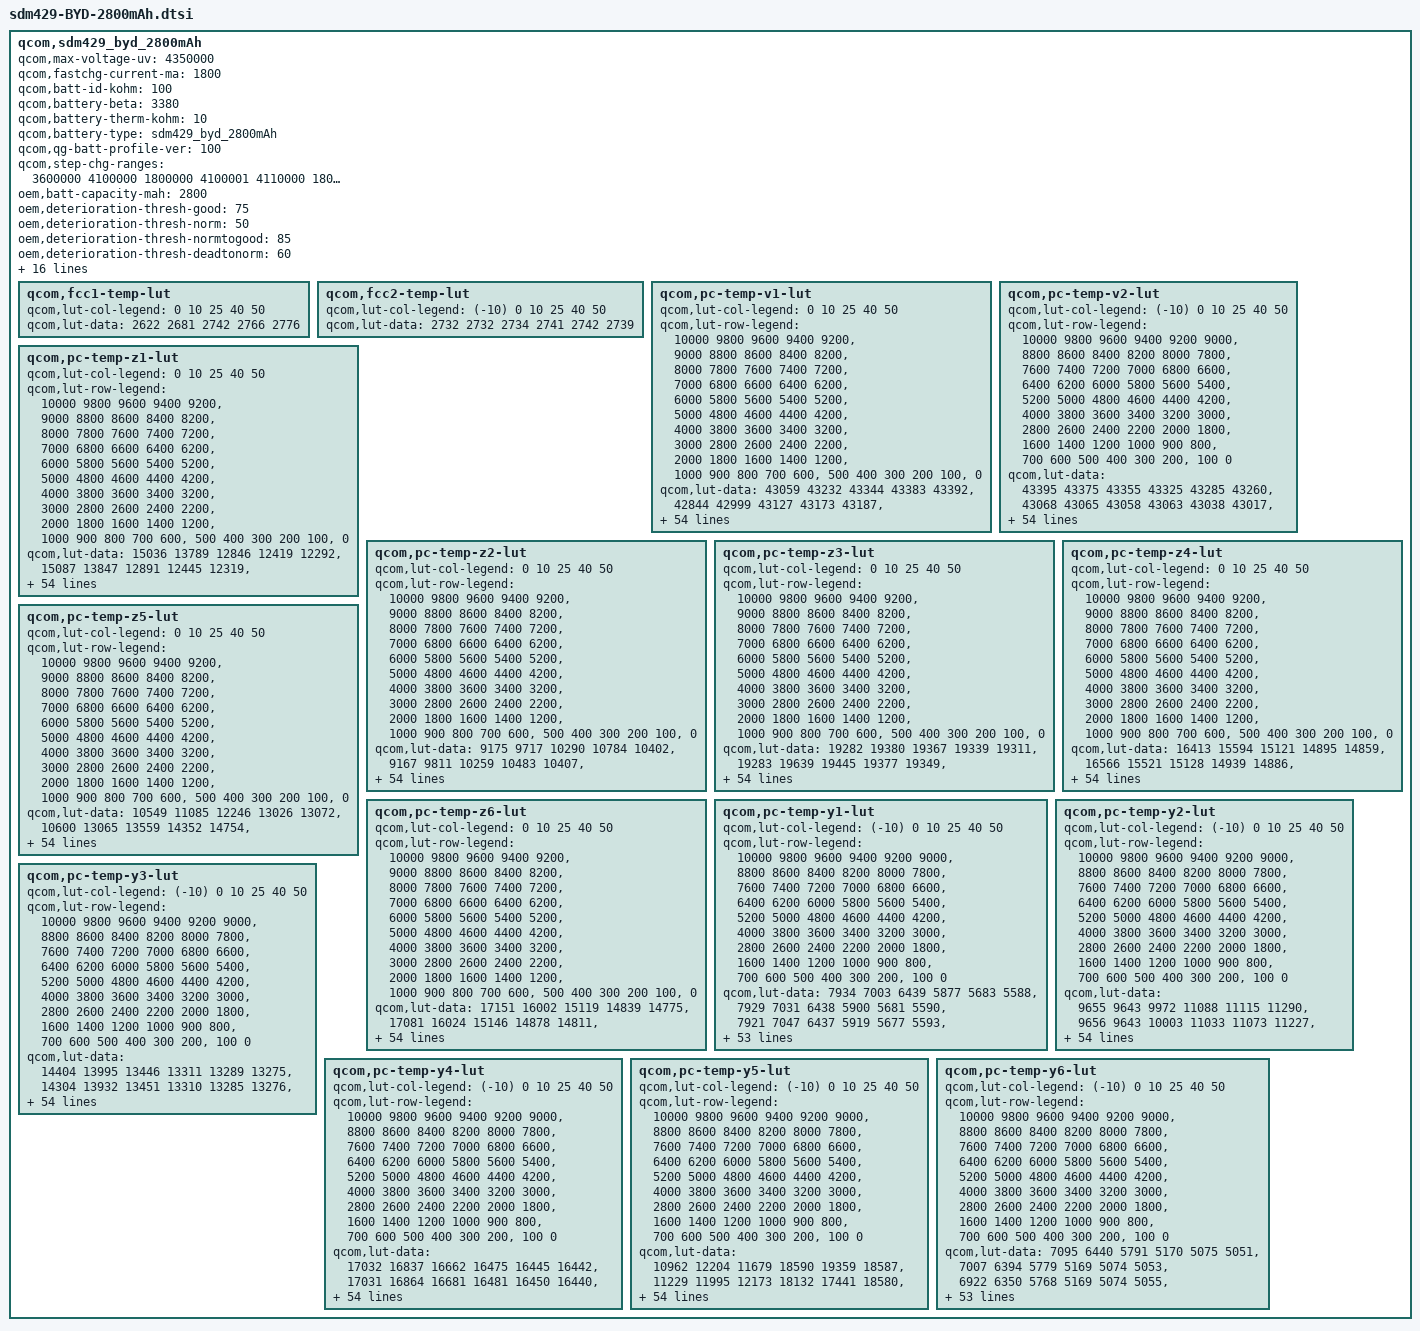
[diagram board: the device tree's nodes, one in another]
/*
 * This software is contributed or developed by KYOCERA Corporation.
 * (C) 2019 KYOCERA Corporation
 *
 * This program is free software; you can redistribute it and/or modify
 * it under the terms of the GNU General Public License version 2 and
 * only version 2 as published by the Free Software Foundation.
 *
 * This program is distributed in the hope that it will be useful,
 * but WITHOUT ANY WARRANTY; without even the implied warranty of
 * MERCHANTABILITY or FITNESS FOR A PARTICULAR PURPOSE.  See the
 * GNU General Public License for more details.
 */

qcom,sdm429_byd_2800mAh {
	/* 3951649_BYD_CB64_BYD_2800mAH_PMI632_averaged_MasterSlave_Apr20th2019 */
	qcom,max-voltage-uv = <4350000>;
	qcom,fastchg-current-ma = <1800>;
	qcom,batt-id-kohm = <100>;
	qcom,battery-beta = <3380>;
	qcom,battery-therm-kohm = <10>;
    qcom,battery-type = "sdm429_byd_2800mAh";
	qcom,qg-batt-profile-ver = <100>;
	qcom,step-chg-ranges = <3600000 4100000 1800000
		4100001 4110000 1800000
		4110001 4120000 1700000
		4120001 4130000 1600000
		4130001 4140000 1500000
		4140001 4150000 1400000
		4150001 4450000 1300000>;

	oem,batt-capacity-mah = <2800>;
	oem,deterioration-thresh-good = <75>;
	oem,deterioration-thresh-norm = <50>;
	oem,deterioration-thresh-normtogood = <85>;
	oem,deterioration-thresh-deadtonorm = <60>;
	oem,cycle-count-thresh = <50 200 500 1000>;
	oem,cycle-count-voltage-comp-mv = <0 50 100 150>;
	oem,cont-chg-thresh = <1000 52000 104000 312000>;
	oem,cont-chg-voltage-comp-mv = <0 50 100 150>;
	oem,batt-temp-thresh = <(-1250) 300 320 360 380 400 420 440 460>;
	oem,cont-chg-factor = <3 4 5 8 11 15 22 32 46>;
	oem,cont-chg-factor-care-mode = <1 2 2 3 4 5 7 10 15>;
	oem,batt-care-max-voltage-uv = <4200000>;

	qcom,jeita-soft-thresholds = <0x2767 0x1149>;
	qcom,jeita-hard-thresholds = <0x32f2 0x0dbf>;
	qcom,jeita-fcc-ranges = <0  30  0
		  30 130   400000
		 131 420  1800000
		 421 500   400000
		 500 600        0>;
	qcom,jeita-fv-ranges =  <30  130  4100000
		 131 420  4350000
		 421 500  4100000>;

	qcom,fcc1-temp-lut {
		qcom,lut-col-legend = <0 10 25 40 50>;
		qcom,lut-data = <2622 2681 2742 2766 2776>;
	};

	qcom,fcc2-temp-lut {
		qcom,lut-col-legend = <(-10) 0 10 25 40 50>;
		qcom,lut-data = <2732 2732 2734 2741 2742 2739>;
	};

	qcom,pc-temp-v1-lut {
		qcom,lut-col-legend = <0 10 25 40 50>;
		qcom,lut-row-legend = <10000 9800 9600 9400 9200>,
			<9000 8800 8600 8400 8200>,
			<8000 7800 7600 7400 7200>,
			<7000 6800 6600 6400 6200>,
			<6000 5800 5600 5400 5200>,
			<5000 4800 4600 4400 4200>,
			<4000 3800 3600 3400 3200>,
			<3000 2800 2600 2400 2200>,
			<2000 1800 1600 1400 1200>,
			<1000 900 800 700 600>,
			<500 400 300 200 100>,
			<0>;
		qcom,lut-data = <43059 43232 43344 43383 43392>,
			<42844 42999 43127 43173 43187>,
			<42622 42767 42904 42957 42977>,
			<42391 42538 42676 42734 42758>,
			<42160 42315 42449 42507 42533>,
			<41941 42097 42224 42282 42310>,
			<41736 41886 42001 42058 42085>,
			<41540 41680 41783 41836 41863>,
			<41358 41483 41567 41618 41644>,
			<41190 41297 41358 41403 41426>,
			<41008 41124 41164 41192 41213>,
			<40784 40937 40982 40983 41005>,
			<40524 40707 40787 40781 40802>,
			<40282 40457 40558 40587 40605>,
			<40073 40237 40328 40397 40414>,
			<39898 40043 40147 40218 40231>,
			<39759 39880 39998 40053 40062>,
			<39641 39746 39848 39883 39892>,
			<39526 39627 39689 39691 39702>,
			<39408 39496 39517 39482 39495>,
			<39290 39350 39304 39278 39295>,
			<39175 39198 39044 39075 39099>,
			<39062 39038 38843 38901 38926>,
			<38951 38862 38730 38776 38791>,
			<38844 38708 38645 38674 38679>,
			<38741 38585 38563 38576 38575>,
			<38645 38482 38486 38477 38475>,
			<38557 38407 38413 38385 38381>,
			<38474 38349 38339 38304 38295>,
			<38402 38301 38269 38231 38215>,
			<38338 38258 38209 38167 38145>,
			<38285 38221 38158 38108 38083>,
			<38248 38186 38111 38054 38027>,
			<38221 38154 38068 37999 37969>,
			<38191 38123 38029 37947 37914>,
			<38151 38087 37987 37894 37855>,
			<38105 38047 37946 37843 37790>,
			<38051 37998 37898 37787 37720>,
			<37987 37925 37824 37713 37640>,
			<37911 37829 37719 37618 37550>,
			<37815 37722 37606 37512 37447>,
			<37694 37595 37486 37392 37326>,
			<37561 37465 37355 37259 37193>,
			<37420 37331 37206 37110 37045>,
			<37295 37228 37103 37007 36947>,
			<37216 37156 37047 36959 36899>,
			<37186 37132 37034 36943 36885>,
			<37162 37109 37018 36930 36874>,
			<37133 37084 36995 36907 36848>,
			<37047 37007 36911 36802 36721>,
			<36775 36721 36596 36471 36383>,
			<36322 36280 36155 36029 35939>,
			<35760 35722 35588 35459 35365>,
			<34998 34964 34817 34684 34584>,
			<33773 33775 33616 33477 33367>,
			<30000 30000 30000 30000 30000>;
	};

	qcom,pc-temp-v2-lut {
		qcom,lut-col-legend = <(-10) 0 10 25 40 50>;
		qcom,lut-row-legend = <10000 9800 9600 9400 9200 9000>,
			<8800 8600 8400 8200 8000 7800>,
			<7600 7400 7200 7000 6800 6600>,
			<6400 6200 6000 5800 5600 5400>,
			<5200 5000 4800 4600 4400 4200>,
			<4000 3800 3600 3400 3200 3000>,
			<2800 2600 2400 2200 2000 1800>,
			<1600 1400 1200 1000 900 800>,
			<700 600 500 400 300 200>,
			<100 0>;
		qcom,lut-data = <43395 43375 43355 43325 43285 43260>,
			<43068 43065 43058 43063 43038 43017>,
			<42763 42773 42781 42811 42798 42781>,
			<42482 42502 42523 42571 42564 42550>,
			<42223 42250 42284 42342 42338 42326>,
			<41978 42012 42057 42118 42116 42105>,
			<41740 41784 41833 41895 41895 41883>,
			<41511 41568 41616 41677 41677 41665>,
			<41297 41362 41402 41461 41463 41450>,
			<41106 41163 41188 41244 41250 41239>,
			<40905 40976 40987 41037 41041 41032>,
			<40650 40813 40822 40855 40839 40830>,
			<40348 40665 40678 40686 40641 40632>,
			<40072 40466 40495 40496 40450 40441>,
			<39829 40118 40212 40254 40262 40256>,
			<39610 39751 39904 40020 40080 40077>,
			<39422 39520 39672 39855 39908 39904>,
			<39256 39354 39482 39726 39745 39737>,
			<39102 39198 39300 39569 39560 39550>,
			<38953 39036 39116 39324 39322 39317>,
			<38815 38882 38942 39064 39080 39079>,
			<38688 38740 38790 38878 38901 38902>,
			<38569 38609 38654 38733 38758 38760>,
			<38461 38492 38530 38609 38634 38636>,
			<38363 38389 38415 38498 38522 38524>,
			<38274 38297 38309 38399 38420 38424>,
			<38192 38215 38218 38307 38327 38330>,
			<38116 38143 38139 38220 38240 38241>,
			<38046 38077 38069 38141 38160 38159>,
			<37979 38016 38007 38068 38087 38084>,
			<37917 37960 37951 38002 38020 38015>,
			<37856 37908 37899 37939 37952 37949>,
			<37799 37860 37851 37884 37886 37889>,
			<37742 37813 37803 37829 37818 37822>,
			<37688 37766 37759 37774 37741 37727>,
			<37636 37719 37715 37716 37655 37611>,
			<37581 37666 37668 37652 37571 37508>,
			<37522 37605 37615 37583 37490 37425>,
			<37461 37535 37552 37511 37410 37346>,
			<37400 37457 37476 37434 37330 37266>,
			<37338 37369 37384 37349 37250 37184>,
			<37276 37276 37280 37249 37155 37088>,
			<37212 37180 37157 37122 37026 36957>,
			<37140 37095 37041 36997 36909 36841>,
			<37056 37022 36956 36910 36843 36786>,
			<36953 36956 36898 36876 36816 36764>,
			<36892 36917 36873 36862 36803 36750>,
			<36816 36870 36843 36844 36782 36726>,
			<36708 36801 36795 36804 36734 36667>,
			<36542 36665 36665 36685 36566 36470>,
			<36283 36387 36367 36372 36201 36081>,
			<35892 35937 35891 35886 35702 35578>,
			<35323 35324 35269 35272 35066 34930>,
			<34498 34466 34412 34444 34197 34049>,
			<33166 33162 33147 33253 32989 32764>,
			<27993 27946 29102 27826 27820 27665>;
	};

	qcom,pc-temp-z1-lut {
		qcom,lut-col-legend = <0 10 25 40 50>;
		qcom,lut-row-legend = <10000 9800 9600 9400 9200>,
			<9000 8800 8600 8400 8200>,
			<8000 7800 7600 7400 7200>,
			<7000 6800 6600 6400 6200>,
			<6000 5800 5600 5400 5200>,
			<5000 4800 4600 4400 4200>,
			<4000 3800 3600 3400 3200>,
			<3000 2800 2600 2400 2200>,
			<2000 1800 1600 1400 1200>,
			<1000 900 800 700 600>,
			<500 400 300 200 100>,
			<0>;
		qcom,lut-data = <15036 13789 12846 12419 12292>,
			<15087 13847 12891 12445 12319>,
			<15099 13868 12891 12454 12332>,
			<15096 13871 12865 12448 12333>,
			<15089 13844 12845 12438 12331>,
			<15065 13803 12843 12436 12332>,
			<15015 13782 12847 12438 12341>,
			<14977 13765 12850 12441 12353>,
			<14957 13753 12853 12445 12358>,
			<14940 13756 12856 12449 12361>,
			<14927 13764 12858 12451 12362>,
			<14906 13764 12860 12454 12364>,
			<14868 13731 12858 12456 12366>,
			<14824 13694 12841 12457 12369>,
			<14769 13694 12826 12458 12372>,
			<14736 13713 12833 12460 12376>,
			<14750 13731 12862 12467 12380>,
			<14784 13754 12884 12473 12384>,
			<14805 13784 12893 12478 12388>,
			<14790 13794 12898 12482 12391>,
			<14775 13779 12904 12487 12395>,
			<14780 13763 12912 12494 12400>,
			<14778 13771 12917 12501 12406>,
			<14768 13800 12916 12507 12412>,
			<14758 13818 12914 12512 12418>,
			<14746 13824 12919 12518 12425>,
			<14743 13828 12940 12528 12432>,
			<14746 13830 12958 12538 12438>,
			<14750 13829 12962 12547 12445>,
			<14754 13828 12964 12556 12452>,
			<14762 13838 12966 12564 12458>,
			<14773 13861 12975 12572 12464>,
			<14796 13875 12985 12580 12470>,
			<14835 13881 12989 12585 12475>,
			<14849 13885 12992 12588 12479>,
			<14845 13885 12996 12592 12485>,
			<14842 13888 13004 12597 12490>,
			<14849 13895 13014 12605 12496>,
			<14888 13916 13025 12611 12501>,
			<14930 13940 13038 12617 12506>,
			<14928 13944 13048 12624 12511>,
			<14893 13930 13052 12632 12517>,
			<14886 13926 13053 12640 12523>,
			<14911 13943 13065 12648 12529>,
			<15023 13978 13084 12657 12535>,
			<14913 13949 13071 12655 12540>,
			<14908 13953 13096 12667 12544>,
			<14890 13940 13093 12663 12545>,
			<14944 13933 13096 12675 12549>,
			<14972 13956 13104 12684 12556>,
			<14944 14021 13099 12692 12569>,
			<14975 14031 13109 12708 12586>,
			<15071 14028 13154 12734 12604>,
			<15069 14113 13211 12771 12631>,
			<15069 14113 13211 12771 12631>,
			<15069 14113 13211 12771 12631>;
	};

	qcom,pc-temp-z2-lut {
		qcom,lut-col-legend = <0 10 25 40 50>;
		qcom,lut-row-legend = <10000 9800 9600 9400 9200>,
			<9000 8800 8600 8400 8200>,
			<8000 7800 7600 7400 7200>,
			<7000 6800 6600 6400 6200>,
			<6000 5800 5600 5400 5200>,
			<5000 4800 4600 4400 4200>,
			<4000 3800 3600 3400 3200>,
			<3000 2800 2600 2400 2200>,
			<2000 1800 1600 1400 1200>,
			<1000 900 800 700 600>,
			<500 400 300 200 100>,
			<0>;
		qcom,lut-data = <9175 9717 10290 10784 10402>,
			<9167 9811 10259 10483 10407>,
			<9228 9727 10231 10361 10411>,
			<9452 9698 10208 10367 10428>,
			<9710 9798 10186 10380 10402>,
			<9800 9909 10159 10359 10361>,
			<9806 9916 10131 10315 10334>,
			<9808 9914 10118 10289 10309>,
			<9809 9912 10116 10280 10284>,
			<9813 9910 10118 10272 10268>,
			<9816 9909 10130 10271 10275>,
			<9804 9908 10155 10275 10302>,
			<9778 9902 10176 10279 10331>,
			<9761 9895 10190 10275 10348>,
			<9760 9897 10199 10274 10360>,
			<9766 9918 10205 10285 10369>,
			<9776 9946 10217 10304 10377>,
			<9790 9973 10224 10328 10388>,
			<9800 9999 10220 10370 10420>,
			<9802 10005 10210 10420 10469>,
			<9803 9991 10186 10421 10480>,
			<9803 9973 10134 10325 10445>,
			<9800 9969 10104 10240 10414>,
			<9796 9971 10110 10259 10426>,
			<9797 9972 10124 10327 10462>,
			<9802 9976 10148 10371 10474>,
			<9809 9984 10207 10385 10396>,
			<9816 9992 10250 10382 10296>,
			<9824 10003 10246 10346 10262>,
			<9834 10013 10227 10288 10244>,
			<9850 10020 10214 10269 10237>,
			<9862 10026 10198 10274 10247>,
			<9788 10033 10188 10286 10266>,
			<9556 10045 10194 10315 10296>,
			<9417 10057 10212 10373 10349>,
			<9520 10068 10227 10412 10391>,
			<9762 10077 10238 10435 10417>,
			<9895 10082 10251 10452 10440>,
			<9909 10085 10273 10469 10465>,
			<9877 10088 10303 10495 10495>,
			<9858 10091 10315 10503 10507>,
			<9855 10097 10309 10484 10494>,
			<9829 10244 10306 10468 10481>,
			<9762 10955 10318 10455 10465>,
			<9761 10910 10388 10442 10490>,
			<9898 13834 10440 10479 10482>,
			<9917 17523 10487 10477 10460>,
			<9898 17806 10523 10484 10550>,
			<9834 17101 10522 10513 10683>,
			<9863 16658 10563 10693 10755>,
			<9761 15713 10720 10695 10665>,
			<9596 13458 10752 10624 10622>,
			<9483 14199 10705 10535 10493>,
			<9417 11607 10584 10367 10380>,
			<9417 11607 10584 10367 10380>,
			<9417 11607 10584 10367 10380>;
	};

	qcom,pc-temp-z3-lut {
		qcom,lut-col-legend = <0 10 25 40 50>;
		qcom,lut-row-legend = <10000 9800 9600 9400 9200>,
			<9000 8800 8600 8400 8200>,
			<8000 7800 7600 7400 7200>,
			<7000 6800 6600 6400 6200>,
			<6000 5800 5600 5400 5200>,
			<5000 4800 4600 4400 4200>,
			<4000 3800 3600 3400 3200>,
			<3000 2800 2600 2400 2200>,
			<2000 1800 1600 1400 1200>,
			<1000 900 800 700 600>,
			<500 400 300 200 100>,
			<0>;
		qcom,lut-data = <19282 19380 19367 19339 19311>,
			<19283 19639 19445 19377 19349>,
			<19320 19756 19488 19403 19373>,
			<19517 19791 19515 19420 19384>,
			<19818 19771 19528 19431 19390>,
			<19947 19741 19531 19432 19391>,
			<19943 19726 19531 19432 19391>,
			<19936 19708 19529 19431 19389>,
			<19920 19690 19518 19420 19382>,
			<19885 19679 19508 19399 19371>,
			<19862 19669 19500 19391 19364>,
			<19889 19661 19487 19390 19356>,
			<19948 19662 19478 19387 19349>,
			<19975 19669 19480 19378 19346>,
			<19951 19670 19484 19365 19344>,
			<19904 19655 19476 19361 19344>,
			<19854 19634 19456 19361 19343>,
			<19800 19606 19448 19363 19342>,
			<19762 19575 19462 19374 19346>,
			<19746 19571 19480 19395 19357>,
			<19738 19603 19484 19400 19361>,
			<19742 19645 19485 19384 19346>,
			<19756 19666 19485 19366 19329>,
			<19777 19681 19479 19362 19331>,
			<19799 19689 19469 19360 19346>,
			<19826 19693 19463 19362 19361>,
			<19838 19695 19458 19396 19374>,
			<19840 19694 19456 19431 19384>,
			<19840 19687 19471 19432 19386>,
			<19838 19677 19501 19424 19385>,
			<19832 19666 19511 19416 19382>,
			<19818 19652 19507 19409 19375>,
			<19717 19636 19500 19403 19366>,
			<19446 19615 19495 19399 19360>,
			<19279 19598 19490 19397 19355>,
			<19270 19593 19485 19394 19353>,
			<19267 19591 19480 19392 19355>,
			<19264 19590 19476 19390 19357>,
			<19263 19595 19475 19388 19357>,
			<19262 19603 19474 19382 19353>,
			<19263 19605 19473 19378 19349>,
			<19263 19604 19467 19373 19347>,
			<19263 19575 19462 19370 19346>,
			<19263 19427 19461 19372 19349>,
			<19263 19291 19439 19370 19343>,
			<19262 19259 19419 19354 19336>,
			<19262 19256 19374 19353 19334>,
			<19262 19256 19358 19350 19320>,
			<19263 19256 19364 19345 19313>,
			<19262 19257 19360 19330 19311>,
			<19263 19257 19337 19322 19309>,
			<19266 19257 19329 19324 19309>,
			<19269 19257 19326 19329 19315>,
			<19271 19259 19327 19347 19326>,
			<19271 19259 19327 19347 19326>,
			<19271 19259 19327 19347 19326>;
	};

	qcom,pc-temp-z4-lut {
		qcom,lut-col-legend = <0 10 25 40 50>;
		qcom,lut-row-legend = <10000 9800 9600 9400 9200>,
			<9000 8800 8600 8400 8200>,
			<8000 7800 7600 7400 7200>,
			<7000 6800 6600 6400 6200>,
			<6000 5800 5600 5400 5200>,
			<5000 4800 4600 4400 4200>,
			<4000 3800 3600 3400 3200>,
			<3000 2800 2600 2400 2200>,
			<2000 1800 1600 1400 1200>,
			<1000 900 800 700 600>,
			<500 400 300 200 100>,
			<0>;
		qcom,lut-data = <16413 15594 15121 14895 14859>,
			<16566 15521 15128 14939 14886>,
			<16570 15408 15100 14946 14893>,
			<16393 15312 15031 14917 14874>,
			<16058 15249 14960 14867 14836>,
			<15813 15192 14909 14828 14804>,
			<15694 15140 14868 14795 14777>,
			<15602 15097 14838 14772 14758>,
			<15530 15058 14812 14762 14746>,
			<15472 15022 14790 14755 14737>,
			<15414 14987 14778 14746 14728>,
			<15337 14956 14769 14731 14720>,
			<15246 14920 14761 14719 14712>,
			<15191 14885 14747 14715 14702>,
			<15175 14864 14733 14712 14690>,
			<15165 14853 14728 14706 14679>,
			<15154 14851 14724 14691 14669>,
			<15144 14855 14721 14681 14662>,
			<15137 14860 14714 14689 14671>,
			<15129 14857 14708 14715 14705>,
			<15108 14821 14741 14757 14750>,
			<15081 14786 14864 14840 14821>,
			<15045 14790 14938 14901 14877>,
			<15006 14829 14932 14900 14874>,
			<14966 14859 14915 14884 14840>,
			<14925 14871 14898 14860 14805>,
			<14905 14880 14877 14803 14770>,
			<14899 14872 14853 14746 14738>,
			<14894 14854 14814 14723 14715>,
			<14890 14835 14766 14709 14697>,
			<14886 14821 14739 14699 14685>,
			<14884 14809 14724 14689 14677>,
			<14971 14803 14715 14683 14672>,
			<15245 14802 14709 14684 14674>,
			<15413 14800 14705 14689 14683>,
			<15407 14795 14704 14696 14694>,
			<15389 14786 14706 14704 14708>,
			<15374 14780 14708 14714 14720>,
			<15361 14776 14716 14723 14723>,
			<15349 14774 14732 14732 14725>,
			<15339 14773 14740 14737 14725>,
			<15329 14773 14741 14737 14724>,
			<15313 14800 14742 14737 14723>,
			<15277 14938 14743 14743 14730>,
			<15129 14992 14728 14727 14722>,
			<15102 14997 14708 14704 14694>,
			<15096 14987 14736 14683 14675>,
			<15090 14979 14742 14665 14664>,
			<15083 14974 14727 14661 14663>,
			<15082 14976 14743 14703 14697>,
			<15096 15007 14801 14734 14713>,
			<15126 15027 14815 14735 14713>,
			<15153 15036 14825 14731 14708>,
			<15185 15053 14831 14714 14697>,
			<15185 15053 14831 14714 14697>,
			<15185 15053 14831 14714 14697>;
	};

	qcom,pc-temp-z5-lut {
		qcom,lut-col-legend = <0 10 25 40 50>;
		qcom,lut-row-legend = <10000 9800 9600 9400 9200>,
			<9000 8800 8600 8400 8200>,
			<8000 7800 7600 7400 7200>,
			<7000 6800 6600 6400 6200>,
			<6000 5800 5600 5400 5200>,
			<5000 4800 4600 4400 4200>,
			<4000 3800 3600 3400 3200>,
			<3000 2800 2600 2400 2200>,
			<2000 1800 1600 1400 1200>,
			<1000 900 800 700 600>,
			<500 400 300 200 100>,
			<0>;
		qcom,lut-data = <10549 11085 12246 13026 13072>,
			<10600 13065 13559 14352 14754>,
			<10773 14002 14476 15297 15840>,
			<11331 14328 15163 15902 16241>,
			<12258 14436 15727 16344 16439>,
			<12836 14557 16246 16769 16662>,
			<13024 14577 16608 17253 16989>,
			<13136 14382 16736 17525 17229>,
			<13164 14207 16883 17207 17078>,
			<13061 14253 17122 16479 16868>,
			<12988 14401 17349 16330 16851>,
			<13467 14526 17326 17013 16625>,
			<14683 15292 17395 17571 16363>,
			<15426 16798 18800 17112 16509>,
			<15163 17492 20614 16377 17216>,
			<14489 17160 20391 16332 18071>,
			<13906 16435 18831 17119 19095>,
			<13367 15652 18328 18501 20359>,
			<13036 14869 22433 23718 22868>,
			<12937 14897 28112 32810 27158>,
			<13006 17776 30165 35237 28639>,
			<13230 22392 30828 27511 22813>,
			<13774 26998 30507 18992 16053>,
			<14619 32286 27384 16246 14850>,
			<15807 35698 22691 14774 14608>,
			<17366 36755 19905 14551 14624>,
			<18612 36610 17969 16777 15474>,
			<19640 35239 17137 19654 16990>,
			<20659 32564 18728 20803 18763>,
			<21143 29673 22591 21565 21068>,
			<20889 27128 24892 22567 22891>,
			<20134 24618 26292 24426 24324>,
			<17998 22434 27541 26622 25261>,
			<13481 20191 28772 28564 25304>,
			<10788 18714 29888 30404 24931>,
			<10728 18637 30147 30988 24497>,
			<10726 18879 29404 29416 23796>,
			<10726 19274 28295 26793 22691>,
			<10734 20761 27361 24230 21272>,
			<10748 22745 26294 21205 19344>,
			<10765 23270 25068 19095 17947>,
			<10789 23305 23265 18005 17276>,
			<10822 22427 21934 17318 16802>,
			<10883 16782 21413 16839 16338>,
			<11160 12105 20546 17516 16160>,
			<11115 11190 19599 16826 16541>,
			<11098 11120 14784 17747 17277>,
			<11085 11105 13811 18731 16613>,
			<11084 11099 14260 18872 16415>,
			<11121 11151 14005 14527 13750>,
			<11182 11218 12578 12918 12835>,
			<11179 11155 12211 12857 12780>,
			<11077 11046 12000 12934 12957>,
			<11020 10984 11915 13830 13600>,
			<11020 10984 11915 13830 13600>,
			<11020 10984 11915 13830 13600>;
	};

	qcom,pc-temp-z6-lut {
		qcom,lut-col-legend = <0 10 25 40 50>;
		qcom,lut-row-legend = <10000 9800 9600 9400 9200>,
			<9000 8800 8600 8400 8200>,
			<8000 7800 7600 7400 7200>,
			<7000 6800 6600 6400 6200>,
			<6000 5800 5600 5400 5200>,
			<5000 4800 4600 4400 4200>,
			<4000 3800 3600 3400 3200>,
			<3000 2800 2600 2400 2200>,
			<2000 1800 1600 1400 1200>,
			<1000 900 800 700 600>,
			<500 400 300 200 100>,
			<0>;
		qcom,lut-data = <17151 16002 15119 14839 14775>,
			<17081 16024 15146 14878 14811>,
			<17009 15969 15142 14891 14825>,
			<16938 15891 15117 14883 14822>,
			<16864 15814 15085 14868 14811>,
			<16779 15738 15059 14854 14800>,
			<16681 15677 15034 14841 14791>,
			<16586 15626 15013 14828 14781>,
			<16503 15582 14994 14816 14772>,
			<16429 15545 14978 14805 14764>,
			<16365 15511 14967 14796 14756>,
			<16311 15476 14959 14789 14749>,
			<16265 15439 14949 14782 14742>,
			<16219 15407 14940 14775 14736>,
			<16173 15389 14932 14768 14730>,
			<16128 15376 14926 14762 14725>,
			<16087 15368 14920 14758 14721>,
			<16050 15362 14917 14755 14718>,
			<16023 15358 14921 14763 14724>,
			<16006 15357 14931 14786 14746>,
			<15992 15363 14956 14811 14768>,
			<15981 15374 15011 14839 14792>,
			<15974 15390 15041 14856 14809>,
			<15969 15417 15038 14855 14809>,
			<15964 15438 15030 14849 14804>,
			<15960 15449 15022 14843 14799>,
			<15960 15457 15012 14838 14792>,
			<15963 15456 15005 14833 14785>,
			<15967 15449 15001 14826 14778>,
			<15969 15440 14998 14817 14771>,
			<15967 15432 14994 14810 14764>,
			<15963 15425 14989 14803 14756>,
			<15956 15418 14984 14798 14750>,
			<15946 15411 14982 14798 14750>,
			<15940 15406 14981 14799 14752>,
			<15939 15406 14981 14801 14754>,
			<15938 15409 14982 14805 14762>,
			<15938 15414 14984 14810 14770>,
			<15944 15421 14990 14813 14771>,
			<15952 15432 15000 14816 14771>,
			<15957 15440 15007 14817 14770>,
			<15961 15447 15008 14816 14770>,
			<15961 15449 15011 14816 14770>,
			<15958 15447 15015 14822 14776>,
			<15910 15416 15003 14816 14771>,
			<15898 15406 14988 14799 14756>,
			<15896 15403 14979 14791 14747>,
			<15894 15401 14973 14781 14735>,
			<15894 15399 14973 14778 14731>,
			<15904 15410 14982 14790 14746>,
			<15926 15437 15001 14803 14756>,
			<15952 15458 15008 14808 14760>,
			<15989 15477 15019 14814 14765>,
			<16039 15514 15034 14824 14772>,
			<16039 15514 15034 14824 14772>,
			<16039 15514 15034 14824 14772>;
	};

	qcom,pc-temp-y1-lut {
		qcom,lut-col-legend = <(-10) 0 10 25 40 50>;
		qcom,lut-row-legend = <10000 9800 9600 9400 9200 9000>,
			<8800 8600 8400 8200 8000 7800>,
			<7600 7400 7200 7000 6800 6600>,
			<6400 6200 6000 5800 5600 5400>,
			<5200 5000 4800 4600 4400 4200>,
			<4000 3800 3600 3400 3200 3000>,
			<2800 2600 2400 2200 2000 1800>,
			<1600 1400 1200 1000 900 800>,
			<700 600 500 400 300 200>,
			<100 0>;
		qcom,lut-data = <7934 7003 6439 5877 5683 5588>,
			<7929 7031 6438 5900 5681 5590>,
			<7921 7047 6437 5919 5677 5593>,
			<7911 7056 6437 5933 5674 5596>,
			<7903 7059 6438 5943 5672 5598>,
			<7899 7059 6439 5948 5671 5599>,
			<7890 7046 6445 5944 5670 5599>,
			<7874 7019 6458 5937 5670 5598>,
			<7868 7010 6465 5935 5671 5598>,
			<7863 7020 6465 5937 5671 5598>,
			<7863 7032 6465 5938 5672 5598>,
			<7884 7046 6468 5937 5672 5598>,
			<7924 7066 6474 5936 5671 5600>,
			<7945 7077 6477 5936 5671 5601>,
			<7945 7070 6489 5942 5672 5602>,
			<7942 7062 6504 5949 5674 5603>,
			<7946 7062 6504 5952 5675 5605>,
			<7966 7064 6498 5951 5677 5607>,
			<7980 7068 6494 5951 5680 5610>,
			<7971 7082 6501 5953 5681 5612>,
			<7951 7099 6513 5955 5683 5614>,
			<7932 7100 6518 5958 5685 5615>,
			<7902 7094 6519 5965 5688 5617>,
			<7886 7090 6517 5972 5691 5619>,
			<7900 7087 6515 5976 5695 5622>,
			<7929 7084 6512 5980 5699 5625>,
			<7950 7084 6507 5982 5703 5628>,
			<7966 7096 6499 5985 5707 5632>,
			<7968 7107 6492 5988 5711 5635>,
			<7948 7107 6500 5995 5715 5638>,
			<7918 7099 6527 6006 5721 5641>,
			<7908 7094 6540 6012 5725 5645>,
			<7916 7095 6532 6012 5729 5649>,
			<7932 7096 6521 6009 5733 5652>,
			<7951 7101 6521 6009 5737 5655>,
			<7975 7122 6528 6011 5741 5658>,
			<7989 7135 6533 6013 5744 5661>,
			<7988 7109 6531 6017 5747 5664>,
			<7982 7074 6526 6021 5750 5666>,
			<7974 7075 6527 6025 5753 5670>,
			<7964 7094 6540 6034 5756 5674>,
			<7956 7102 6553 6041 5761 5678>,
			<7946 7112 6559 6042 5768 5681>,
			<7939 7131 6559 6047 5774 5683>,
			<7977 7130 6557 6064 5777 5688>,
			<8013 7139 6562 6068 5782 5693>,
			<8013 7161 6580 6067 5784 5695>,
			<8019 7173 6601 6070 5783 5698>,
			<8075 7189 6606 6073 5786 5700>,
			<8084 7221 6587 6076 5793 5700>,
			<8097 7205 6623 6086 5802 5710>,
			<8101 7268 6638 6095 5812 5722>,
			<8213 7278 6651 6110 5829 5736>,
			<8274 7350 6711 6141 5854 5756>,
			<8274 7350 6711 6141 5854 5756>,
			<8274 7350 6711 6141 5854 5756>;
	};

	qcom,pc-temp-y2-lut {
		qcom,lut-col-legend = <(-10) 0 10 25 40 50>;
		qcom,lut-row-legend = <10000 9800 9600 9400 9200 9000>,
			<8800 8600 8400 8200 8000 7800>,
			<7600 7400 7200 7000 6800 6600>,
			<6400 6200 6000 5800 5600 5400>,
			<5200 5000 4800 4600 4400 4200>,
			<4000 3800 3600 3400 3200 3000>,
			<2800 2600 2400 2200 2000 1800>,
			<1600 1400 1200 1000 900 800>,
			<700 600 500 400 300 200>,
			<100 0>;
		qcom,lut-data = <9655 9643 9972 11088 11115 11290>,
			<9656 9643 10003 11033 11073 11227>,
			<9658 9645 10041 10980 11032 11156>,
			<9659 9694 10080 10930 10995 11086>,
			<9660 9739 10114 10887 10965 11028>,
			<9661 9774 10137 10852 10948 10992>,
			<9662 9800 10147 10824 10944 10976>,
			<9663 9822 10155 10801 10947 10969>,
			<9664 9838 10171 10791 10949 10969>,
			<9664 9848 10241 10788 10949 10979>,
			<9665 9859 10318 10788 10949 10985>,
			<9665 9940 10354 10790 10950 10988>,
			<9666 10153 10379 10795 10955 11002>,
			<9666 10247 10400 10803 10962 11019>,
			<9666 10014 10423 10837 10984 11050>,
			<9665 9733 10444 10879 11021 11093>,
			<9665 9691 10458 10909 11089 11161>,
			<9665 9689 10470 10942 11199 11264>,
			<9665 9688 10482 10956 11246 11310>,
			<9665 9687 10498 10951 11197 11234>,
			<9664 9686 10514 10944 11125 11131>,
			<9664 9685 10515 10953 11101 11113>,
			<9664 9682 10508 10990 11092 11120>,
			<9664 9679 10501 11014 11089 11132>,
			<9663 9678 10394 11012 11116 11154>,
			<9663 9676 10142 11008 11171 11187>,
			<9663 9675 10043 11010 11206 11222>,
			<9663 9673 10049 11021 11247 11264>,
			<9662 9672 10052 11028 11270 11297>,
			<9662 9671 10050 11030 11279 11327>,
			<9662 9670 10048 11032 11294 11361>,
			<9662 9669 10045 11030 11303 11382>,
			<9661 9668 10039 11022 11303 11416>,
			<9661 9667 10030 11011 11298 11435>,
			<9661 9666 10025 11003 11272 11370>,
			<9661 9666 10016 10995 11228 11221>,
			<9660 9665 9984 10986 11194 11157>,
			<9660 9665 9840 10974 11165 11173>,
			<9660 9665 9720 10960 11150 11202>,
			<9659 9664 9703 10947 11164 11231>,
			<9659 9663 9693 10932 11181 11260>,
			<9659 9662 9685 10910 11177 11268>,
			<9659 9661 9679 10870 11170 11249>,
			<9659 9660 9674 10817 11145 11200>,
			<9658 9659 9670 10755 11036 11091>,
			<9658 9659 9666 10703 10978 10997>,
			<9657 9659 9666 10707 10975 10993>,
			<9657 9659 9667 10716 10973 10974>,
			<9657 9658 9666 10721 10946 10959>,
			<9657 9658 9665 10701 10920 10917>,
			<9656 9657 9663 10670 10900 10867>,
			<9656 9657 9662 10597 10822 10834>,
			<9655 9656 9659 10532 10809 10818>,
			<9652 9655 9658 10489 10798 10779>,
			<9652 9655 9658 10489 10798 10779>,
			<9652 9655 9658 10489 10798 10779>;
	};

	qcom,pc-temp-y3-lut {
		qcom,lut-col-legend = <(-10) 0 10 25 40 50>;
		qcom,lut-row-legend = <10000 9800 9600 9400 9200 9000>,
			<8800 8600 8400 8200 8000 7800>,
			<7600 7400 7200 7000 6800 6600>,
			<6400 6200 6000 5800 5600 5400>,
			<5200 5000 4800 4600 4400 4200>,
			<4000 3800 3600 3400 3200 3000>,
			<2800 2600 2400 2200 2000 1800>,
			<1600 1400 1200 1000 900 800>,
			<700 600 500 400 300 200>,
			<100 0>;
		qcom,lut-data = <14404 13995 13446 13311 13289 13275>,
			<14304 13932 13451 13310 13285 13276>,
			<14208 13862 13456 13309 13284 13278>,
			<14119 13794 13462 13310 13284 13280>,
			<14039 13734 13467 13311 13285 13281>,
			<13971 13693 13469 13313 13287 13282>,
			<13916 13671 13470 13315 13290 13283>,
			<13869 13654 13470 13318 13295 13284>,
			<13827 13630 13468 13319 13298 13286>,
			<13785 13589 13458 13318 13299 13290>,
			<13753 13554 13447 13318 13300 13294>,
			<13735 13542 13444 13321 13300 13295>,
			<13723 13534 13439 13328 13300 13295>,
			<13710 13528 13434 13331 13300 13296>,
			<13690 13520 13431 13325 13302 13297>,
			<13674 13512 13427 13320 13304 13297>,
			<13672 13509 13422 13321 13304 13298>,
			<13674 13508 13414 13325 13302 13296>,
			<13675 13506 13406 13327 13300 13294>,
			<13672 13496 13397 13322 13295 13288>,
			<13667 13482 13387 13314 13290 13282>,
			<13663 13470 13381 13308 13288 13279>,
			<13658 13460 13377 13301 13287 13278>,
			<13656 13454 13372 13298 13286 13278>,
			<13659 13451 13358 13301 13285 13279>,
			<13669 13449 13337 13305 13285 13281>,
			<13680 13449 13330 13307 13285 13281>,
			<13691 13455 13331 13308 13286 13281>,
			<13703 13465 13333 13309 13287 13280>,
			<13718 13476 13335 13310 13289 13280>,
			<13735 13490 13338 13312 13290 13281>,
			<13752 13503 13340 13313 13291 13281>,
			<13767 13516 13348 13314 13291 13282>,
			<13783 13528 13361 13315 13291 13284>,
			<13803 13542 13372 13315 13290 13283>,
			<13826 13557 13383 13315 13289 13280>,
			<13850 13572 13392 13314 13288 13279>,
			<13874 13584 13403 13312 13286 13279>,
			<13899 13597 13412 13311 13284 13280>,
			<13929 13613 13419 13310 13284 13281>,
			<13964 13634 13426 13310 13285 13283>,
			<14002 13656 13436 13309 13286 13284>,
			<14045 13683 13448 13309 13286 13283>,
			<14090 13719 13464 13309 13287 13281>,
			<14142 13767 13492 13310 13289 13282>,
			<14198 13817 13535 13319 13294 13291>,
			<14200 13819 13550 13319 13296 13293>,
			<14192 13811 13551 13323 13299 13293>,
			<14183 13801 13544 13326 13305 13295>,
			<14250 13838 13566 13331 13300 13289>,
			<14328 13884 13586 13328 13296 13287>,
			<14417 13941 13616 13328 13297 13289>,
			<14545 14034 13688 13341 13303 13294>,
			<15010 14146 13775 13353 13308 13297>,
			<15010 14146 13775 13353 13308 13297>,
			<15010 14146 13775 13353 13308 13297>;
	};

	qcom,pc-temp-y4-lut {
		qcom,lut-col-legend = <(-10) 0 10 25 40 50>;
		qcom,lut-row-legend = <10000 9800 9600 9400 9200 9000>,
			<8800 8600 8400 8200 8000 7800>,
			<7600 7400 7200 7000 6800 6600>,
			<6400 6200 6000 5800 5600 5400>,
			<5200 5000 4800 4600 4400 4200>,
			<4000 3800 3600 3400 3200 3000>,
			<2800 2600 2400 2200 2000 1800>,
			<1600 1400 1200 1000 900 800>,
			<700 600 500 400 300 200>,
			<100 0>;
		qcom,lut-data = <17032 16837 16662 16475 16445 16442>,
			<17031 16864 16681 16481 16450 16440>,
			<17036 16888 16701 16487 16454 16440>,
			<17046 16906 16721 16493 16458 16441>,
			<17058 16919 16737 16499 16460 16443>,
			<17073 16924 16749 16503 16461 16445>,
			<17088 16917 16756 16507 16460 16448>,
			<17108 16904 16760 16510 16458 16452>,
			<17134 16907 16770 16515 16458 16453>,
			<17182 16983 16794 16526 16463 16454>,
			<17217 17056 16827 16539 16471 16454>,
			<17172 17062 16882 16554 16481 16458>,
			<17043 17057 16962 16570 16493 16468>,
			<16974 17043 16990 16585 16506 16478>,
			<16959 16951 16891 16597 16517 16489>,
			<16950 16849 16764 16610 16529 16501>,
			<16943 16829 16721 16629 16551 16519>,
			<16937 16825 16703 16655 16581 16544>,
			<16930 16819 16684 16662 16592 16554>,
			<16921 16801 16656 16595 16548 16523>,
			<16913 16783 16630 16510 16488 16478>,
			<16910 16780 16616 16495 16469 16462>,
			<16908 16780 16606 16495 16461 16456>,
			<16907 16781 16601 16497 16458 16453>,
			<16907 16785 16612 16497 16463 16456>,
			<16906 16794 16639 16496 16472 16461>,
			<16906 16800 16650 16496 16482 16468>,
			<16906 16803 16652 16503 16492 16480>,
			<16906 16803 16655 16511 16503 16494>,
			<16908 16803 16661 16520 16515 16507>,
			<16913 16802 16671 16529 16527 16520>,
			<16918 16804 16680 16537 16532 16529>,
			<16924 16808 16687 16545 16534 16536>,
			<16929 16813 16693 16549 16535 16539>,
			<16934 16819 16702 16548 16527 16525>,
			<16938 16826 16713 16541 16507 16491>,
			<16944 16831 16725 16534 16493 16473>,
			<16955 16834 16741 16526 16485 16468>,
			<16971 16831 16755 16521 16481 16465>,
			<16988 16828 16766 16522 16482 16464>,
			<17009 16827 16771 16524 16484 16464>,
			<17034 16827 16767 16526 16484 16463>,
			<17069 16826 16760 16526 16479 16459>,
			<17109 16834 16756 16520 16471 16456>,
			<17150 16859 16761 16516 16465 16456>,
			<17157 16896 16784 16533 16483 16464>,
			<17108 16903 16781 16551 16495 16472>,
			<17036 16894 16777 16559 16502 16483>,
			<16961 16868 16789 16570 16503 16488>,
			<16963 16872 16795 16562 16488 16474>,
			<16952 16846 16766 16530 16468 16456>,
			<16938 16827 16758 16528 16471 16458>,
			<16943 16834 16775 16537 16481 16467>,
			<17132 16859 16801 16570 16524 16518>,
			<17132 16859 16801 16570 16524 16518>,
			<17132 16859 16801 16570 16524 16518>;
	};

	qcom,pc-temp-y5-lut {
		qcom,lut-col-legend = <(-10) 0 10 25 40 50>;
		qcom,lut-row-legend = <10000 9800 9600 9400 9200 9000>,
			<8800 8600 8400 8200 8000 7800>,
			<7600 7400 7200 7000 6800 6600>,
			<6400 6200 6000 5800 5600 5400>,
			<5200 5000 4800 4600 4400 4200>,
			<4000 3800 3600 3400 3200 3000>,
			<2800 2600 2400 2200 2000 1800>,
			<1600 1400 1200 1000 900 800>,
			<700 600 500 400 300 200>,
			<100 0>;
		qcom,lut-data = <10962 12204 11679 18590 19359 18587>,
			<11229 11995 12173 18132 17441 18580>,
			<11551 11963 12725 17510 16262 18445>,
			<11864 12066 13274 16842 15641 18210>,
			<12108 12260 13757 16242 15400 17900>,
			<12219 12505 14110 15828 15359 17540>,
			<12185 12927 14361 15601 16100 17005>,
			<12107 13444 14563 15398 17542 16413>,
			<12103 13536 14534 15133 17919 16372>,
			<12440 13012 13799 14369 17271 17497>,
			<12856 12531 13141 13722 16365 18505>,
			<13169 14197 13677 13755 15453 18076>,
			<13542 18694 15396 13965 14488 16750>,
			<13626 20509 17009 14041 14112 15777>,
			<13005 17208 18588 13778 14037 15107>,
			<12335 13333 19707 13537 13998 14674>,
			<12280 12796 19762 14304 14038 14612>,
			<12338 12915 19538 17072 14395 14610>,
			<12374 12984 19203 19025 15018 14725>,
			<12303 12907 18485 19731 17215 16191>,
			<12160 12766 17597 20035 19387 18100>,
			<12032 12554 17011 19108 19537 18335>,
			<11895 12211 16603 16297 19128 17477>,
			<11824 11940 16153 14660 18537 16791>,
			<11823 11785 15031 15425 17368 16909>,
			<11826 11650 13356 16728 16172 17142>,
			<11841 11584 12762 17306 15973 16963>,
			<11904 11625 12720 17586 16091 15926>,
			<11970 11740 12706 17814 16286 15275>,
			<12009 11875 12711 18207 16710 15248>,
			<12027 12033 12690 18688 17309 15249>,
			<12044 12189 12658 19086 17583 15373>,
			<12060 12362 12688 19535 17639 16214>,
			<12081 12526 12799 19983 17673 16973>,
			<12150 12682 12948 20352 17749 16949>,
			<12249 12851 13163 20323 17853 16635>,
			<12281 12949 13282 19746 17797 16509>,
			<12206 12959 13250 18394 16913 16840>,
			<12111 12937 13192 17251 15862 17145>,
			<12044 12892 13094 16658 15467 17188>,
			<12082 12675 13011 15973 15274 17230>,
			<12210 12446 12974 15422 15241 17361>,
			<12322 12272 12694 15153 15685 17432>,
			<12430 12261 12253 15080 16518 16966>,
			<12552 12322 12205 14817 17034 16410>,
			<12768 12486 12175 14808 15349 17202>,
			<13081 12488 12387 13979 14592 16401>,
			<13442 12563 12533 14049 14415 15596>,
			<13586 12967 12800 14064 16230 16581>,
			<13563 13157 12923 15107 16199 15983>,
			<13478 13135 13119 16042 17132 17203>,
			<13429 12770 12729 16109 17571 19745>,
			<13071 12574 12723 18075 21785 23921>,
			<12115 12785 13077 20580 23769 24422>,
			<12115 12785 13077 20580 23769 24422>,
			<12115 12785 13077 20580 23769 24422>;
	};

	qcom,pc-temp-y6-lut {
		qcom,lut-col-legend = <(-10) 0 10 25 40 50>;
		qcom,lut-row-legend = <10000 9800 9600 9400 9200 9000>,
			<8800 8600 8400 8200 8000 7800>,
			<7600 7400 7200 7000 6800 6600>,
			<6400 6200 6000 5800 5600 5400>,
			<5200 5000 4800 4600 4400 4200>,
			<4000 3800 3600 3400 3200 3000>,
			<2800 2600 2400 2200 2000 1800>,
			<1600 1400 1200 1000 900 800>,
			<700 600 500 400 300 200>,
			<100 0>;
		qcom,lut-data = <7095 6440 5791 5170 5075 5051>,
			<7007 6394 5779 5169 5074 5053>,
			<6922 6350 5768 5169 5074 5055>,
			<6842 6309 5758 5169 5075 5057>,
			<6772 6269 5748 5170 5076 5058>,
			<6713 6233 5738 5170 5078 5060>,
			<6665 6197 5729 5171 5080 5062>,
			<6624 6165 5720 5172 5082 5064>,
			<6593 6140 5711 5173 5084 5066>,
			<6571 6119 5700 5175 5087 5068>,
			<6549 6106 5693 5178 5090 5071>,
			<6513 6102 5697 5183 5093 5074>,
			<6465 6101 5708 5190 5096 5077>,
			<6435 6095 5711 5195 5100 5080>,
			<6420 6047 5686 5197 5104 5084>,
			<6410 5993 5651 5198 5109 5088>,
			<6408 5983 5634 5204 5115 5093>,
			<6410 5982 5625 5215 5122 5099>,
			<6410 5979 5615 5219 5124 5101>,
			<6408 5970 5600 5196 5109 5088>,
			<6405 5957 5587 5166 5087 5070>,
			<6402 5952 5582 5158 5080 5064>,
			<6399 5951 5580 5155 5077 5061>,
			<6398 5951 5579 5154 5076 5060>,
			<6402 5955 5579 5157 5078 5062>,
			<6412 5962 5581 5161 5080 5065>,
			<6422 5969 5584 5165 5084 5068>,
			<6432 5977 5593 5169 5088 5071>,
			<6443 5987 5605 5173 5092 5075>,
			<6456 5999 5616 5178 5097 5079>,
			<6471 6012 5630 5184 5102 5083>,
			<6487 6027 5644 5190 5105 5087>,
			<6503 6042 5660 5195 5106 5090>,
			<6520 6058 5676 5200 5107 5092>,
			<6540 6076 5693 5202 5105 5087>,
			<6560 6096 5712 5203 5099 5076>,
			<6582 6115 5731 5202 5095 5071>,
			<6606 6131 5751 5201 5092 5071>,
			<6634 6147 5772 5200 5090 5071>,
			<6665 6167 5794 5203 5091 5071>,
			<6701 6190 5818 5207 5093 5073>,
			<6741 6216 5842 5211 5094 5073>,
			<6787 6245 5867 5215 5094 5072>,
			<6840 6282 5896 5219 5092 5070>,
			<6906 6332 5939 5225 5093 5072>,
			<6968 6394 5998 5245 5104 5082>,
			<6965 6405 6011 5251 5109 5086>,
			<6949 6399 6011 5257 5113 5089>,
			<6940 6392 6008 5264 5118 5093>,
			<7006 6435 6036 5267 5111 5084>,
			<7076 6472 6061 5262 5104 5078>,
			<7160 6531 6107 5269 5107 5082>,
			<7298 6624 6200 5296 5116 5090>,
			<7848 6742 6304 5330 5136 5109>,
			<7848 6742 6304 5330 5136 5109>,
			<7848 6742 6304 5330 5136 5109>;
	};

};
